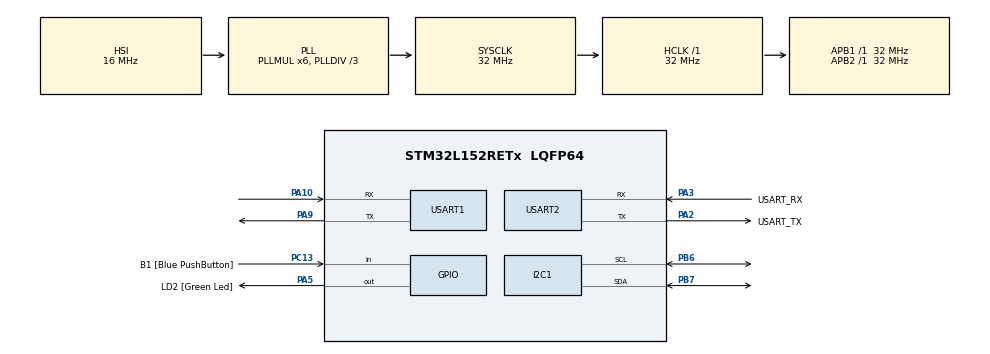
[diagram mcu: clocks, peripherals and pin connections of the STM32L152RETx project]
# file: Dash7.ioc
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Mcu.Family=STM32L1
Mcu.Name=STM32L152RETx
Mcu.Package=LQFP64
NVIC.PriorityGroup=NVIC_PRIORITYGROUP_0
PA10.Mode=Asynchronous
PA10.Signal=USART1_RX
PA13.GPIO_Label=TMS
PA13.Signal=SYS_JTMS-SWDIO
PA14.GPIO_Label=TCK
PA14.Signal=SYS_JTCK-SWCLK
PA2.GPIO_Label=USART_TX
PA2.Mode=Asynchronous
PA2.Signal=USART2_TX
PA3.GPIO_Label=USART_RX
PA3.Mode=Asynchronous
PA3.Signal=USART2_RX
PA5.GPIO_Label=LD2 [Green Led]
PA5.Signal=GPIO_Output
PA9.Mode=Asynchronous
PA9.Signal=USART1_TX
PB3.GPIO_Label=SWO
PB3.Signal=SYS_JTDO-TRACESWO
PB6.Mode=I2C
PB6.Signal=I2C1_SCL
PB7.Mode=I2C
PB7.Signal=I2C1_SDA
PC13-WKUP2.GPIO_Label=B1 [Blue PushButton]
PC13-WKUP2.Signal=GPIO_Input
PC14-OSC32_IN.Signal=RCC_OSC32_IN
PC15-OSC32_OUT.Signal=RCC_OSC32_OUT
PH0-OSC_IN.Signal=RCC_OSC_IN
PH1-OSC_OUT.Signal=RCC_OSC_OUT
ProjectManager.HeapSize=0x200
ProjectManager.StackSize=0x400
ProjectManager.TargetToolchain=EWARM
RCC.AHBFreq_Value=32000000
RCC.APB1Freq_Value=32000000
RCC.APB1TimFreq_Value=32000000
RCC.APB2Freq_Value=32000000
RCC.APB2TimFreq_Value=32000000
RCC.HCLKFreq_Value=32000000
RCC.HSE_VALUE=8000000
RCC.HSI_VALUE=16000000
RCC.LSE_VALUE=32768
RCC.MSI_VALUE=2097000
RCC.PLLDIV=RCC_PLL_DIV3
RCC.PLLMUL=RCC_PLL_MUL6
RCC.RTCClockSelectionVirtual=RCC_RTCCLKSOURCE_LSE
RCC.SYSCLKFreq_VALUE=32000000
RCC.SYSCLKSource=RCC_SYSCLKSOURCE_PLLCLK
RCC.USBOutput=48000000
RCC.VCOOutputFreq_Value=96000000
board=NUCLEO-L152RE

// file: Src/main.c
/**
  ******************************************************************************
  * File Name          : main.c
  * Description        : Main program body
  ******************************************************************************
  *
  * COPYRIGHT(c) 2017 STMicroelectronics
  *
  * Redistribution and use in source and binary forms, with or without modification,
  * are permitted provided that the following conditions are met:
  *   1. Redistributions of source code must retain the above copyright notice,
  *      this list of conditions and the following disclaimer.
  *   2. Redistributions in binary form must reproduce the above copyright notice,
  *      this list of conditions and the following disclaimer in the documentation
  *      and/or other materials provided with the distribution.
  *   3. Neither the name of STMicroelectronics nor the names of its contributors
  *      may be used to endorse or promote products derived from this software
  *      without specific prior written permission.
  *
  * THIS SOFTWARE IS PROVIDED BY THE COPYRIGHT HOLDERS AND CONTRIBUTORS "AS IS"
  * AND ANY EXPRESS OR IMPLIED WARRANTIES, INCLUDING, BUT NOT LIMITED TO, THE
  * IMPLIED WARRANTIES OF MERCHANTABILITY AND FITNESS FOR A PARTICULAR PURPOSE ARE
  * DISCLAIMED. IN NO EVENT SHALL THE COPYRIGHT HOLDER OR CONTRIBUTORS BE LIABLE
  * FOR ANY DIRECT, INDIRECT, INCIDENTAL, SPECIAL, EXEMPLARY, OR CONSEQUENTIAL
  * DAMAGES (INCLUDING, BUT NOT LIMITED TO, PROCUREMENT OF SUBSTITUTE GOODS OR
  * SERVICES; LOSS OF USE, DATA, OR PROFITS; OR BUSINESS INTERRUPTION) HOWEVER
  * CAUSED AND ON ANY THEORY OF LIABILITY, WHETHER IN CONTRACT, STRICT LIABILITY,
  * OR TORT (INCLUDING NEGLIGENCE OR OTHERWISE) ARISING IN ANY WAY OUT OF THE USE
  * OF THIS SOFTWARE, EVEN IF ADVISED OF THE POSSIBILITY OF SUCH DAMAGE.
  *
  ******************************************************************************
  */

#include "main.h"
#include "stm32l1xx_hal.h"

/* USER CODE BEGIN Includes */
/* USER CODE BEGIN Includes */
#ifdef __GNUC__
/* With GCC/RAISONANCE, small printf (option LD Linker->Libraries->Small printf
   set to 'Yes') calls __io_putchar() */
#define PUTCHAR_PROTOTYPE int __io_putchar(int ch)
#else
#define PUTCHAR_PROTOTYPE int fputc(int ch, FILE *f)
#endif /* __GNUC__ */
/* USER CODE END Includes */

I2C_HandleTypeDef hi2c1;

UART_HandleTypeDef huart1;
UART_HandleTypeDef huart2;

/* USER CODE BEGIN PV */
/* Private variables ---------------------------------------------------------*/

/* USER CODE END PV */

void SystemClock_Config(void);
void Error_Handler(void);
void Dash7Send(void);
static void MX_GPIO_Init(void);
static void MX_I2C1_Init(void);
static void MX_USART1_UART_Init(void);
static void MX_USART2_UART_Init(void);

/* USER CODE BEGIN PFP */
/* Private function prototypes -----------------------------------------------*/

/* USER CODE END PFP */

int main(void)
{

  /* MCU Configuration----------------------------------------------------------*/

  /* Reset of all peripherals, Initializes the Flash interface and the Systick. */
  HAL_Init();

  /* Configure the system clock */
  SystemClock_Config();

  /* Initialize all configured peripherals */
  MX_GPIO_Init();
  MX_I2C1_Init();
  MX_USART1_UART_Init();
  MX_USART2_UART_Init();

  /* USER CODE BEGIN 2 */
    uint8_t opt = 0;
    char readBuf[1];
  /* USER CODE END 2 */

  /* Infinite loop */
  while (1)
  {

  /* USER CODE BEGIN 3 */
      if(HAL_GPIO_ReadPin(B1_GPIO_Port, B1_Pin) == GPIO_PIN_RESET) {
	          HAL_GPIO_TogglePin(LD2_GPIO_Port, LD2_Pin);
                  Dash7Send();
	          HAL_Delay(500);
      }

  }
  /* USER CODE END 3 */

}

/*
    -----------------------------FULL COMMAND WITH DATA [0,1] -------------------
    41 54 24 44 c0 00 0e b4 af 32 d7 01 00 10 01 20 01 00 02 00 01
    0x41 0x54 0x24 0x44 0xc0 0x00 0x0e 0xb4 0xaf 0x32 0xd7 0x01 0x00 0x10 0x01 0x20 0x01 0x00 0x02 0x00 0x01
    $41 $54 $24 $44 $c0 $00 $0e $b4 $af $32 $d7 $01 $00 $10 $01 $20 $01 $00 $02 $00 $01

            ---------------------SERIALIZE------------------------
    41 54 24 44 c0 00 0e

        STATIC SER       LENGTH
    [41 54 24 44 c0 00]  [0e]

    ++++++++++++++++ LENGTH ++++++++++++++++
    Length of bytes of the ALP COMMAND

    0e --> 14 --> Length

            ---------------------ALP COMMAND----------------------
    34 af 32 d7 01 00 10 01 20 01 00 02 00 01

      TAG         FORWARD         RETURN FILE DATA
    [34 af] [32 d7 01 00 10 01] [20 01 00 02 00 01]

    ++++++++++++++++ TAG ++++++++++++++++

    ALP COMMAND:
    34 af

    34 --> 52   --> Request Tag
    af --> 175  --> Tag Value (random)

    PARSED: Command with tag 175 (executing)

    ++++++++++++++++ FORWARD ++++++++++++++++

    ALP COMMAND:
    32 d7 01 00 10 01

    32 --> 50    --> Forward
    d7 --> 215   --> Interface Name (D7ASP)
    01 --> 01    --> ResponseMode.RESP_MODE_ANY
    00 --> 00    --> mant
    10 --> 16    --> ??
    01 --> 01    --> access_class

    PARSED:
    actions:
	action: Forward: interface-id=InterfaceType.D7ASP, configuration={'addressee': {'nls_method': <NlsMethod.NONE: 0>, 'access_class': 1,
            '__CLASS__': 'Addressee', 'id_type': <IdType.NOID: 1>, 'id': None}, 'qos': {'record': False, 'resp_mod': <ResponseMode.RESP_MODE_ALL: 1>,
            '__CLASS__': 'QoS', 'retry_mod': <RetryMode.RETRY_MODE_NO: 0>, 'stop_on_err': False}, '__CLASS__': 'Configuration', 'dorm_to': {'mant': 0, '__CLASS__': 'CT', 'exp': 0}}

    ++++++++++++++ RETURN FILE DATA ++++++++++++++++

    ALP COMMAND:
    20 01 00 02 00 01

    20 --> 32   --> Return File Data
    01 --> 01   --> File ID
    00 --> 00   --> Offset
    02 --> 02   --> Length data bytes

    <DATA> [0,1] LENGTH:2
    00 --> 00
    00 --> 01

    PARSED:
    actions:
        action: ReturnFileData: file-id=1, size=1, offset=0, length=2, data=[0, 1]
*/
void Dash7Send(void)
{
  uint8_t message[] = {0x41, 0x54, 0x24, 0x44, 0xc0, 0x00, 0x0e, 0xb4, 0xaf, 0x32, 0xd7, 0x01, 0x00, 0x10, 0x01, 0x20, 0x01, 0x00, 0x02, 0x00, 0x01};
  HAL_UART_Transmit(&huart1, (uint8_t*)message, sizeof(message), HAL_MAX_DELAY);
}

/** System Clock Configuration
*/
void SystemClock_Config(void)
{

  RCC_OscInitTypeDef RCC_OscInitStruct;
  RCC_ClkInitTypeDef RCC_ClkInitStruct;

    /**Configure the main internal regulator output voltage
    */
  __HAL_PWR_VOLTAGESCALING_CONFIG(PWR_REGULATOR_VOLTAGE_SCALE1);

    /**Initializes the CPU, AHB and APB busses clocks
    */
  RCC_OscInitStruct.OscillatorType = RCC_OSCILLATORTYPE_HSI;
  RCC_OscInitStruct.HSIState = RCC_HSI_ON;
  RCC_OscInitStruct.HSICalibrationValue = 16;
  RCC_OscInitStruct.PLL.PLLState = RCC_PLL_ON;
  RCC_OscInitStruct.PLL.PLLSource = RCC_PLLSOURCE_HSI;
  RCC_OscInitStruct.PLL.PLLMUL = RCC_PLL_MUL6;
  RCC_OscInitStruct.PLL.PLLDIV = RCC_PLL_DIV3;
  if (HAL_RCC_OscConfig(&RCC_OscInitStruct) != HAL_OK)
  {
    Error_Handler();
  }

    /**Initializes the CPU, AHB and APB busses clocks
    */
  RCC_ClkInitStruct.ClockType = RCC_CLOCKTYPE_HCLK|RCC_CLOCKTYPE_SYSCLK
                              |RCC_CLOCKTYPE_PCLK1|RCC_CLOCKTYPE_PCLK2;
  RCC_ClkInitStruct.SYSCLKSource = RCC_SYSCLKSOURCE_PLLCLK;
  RCC_ClkInitStruct.AHBCLKDivider = RCC_SYSCLK_DIV1;
  RCC_ClkInitStruct.APB1CLKDivider = RCC_HCLK_DIV1;
  RCC_ClkInitStruct.APB2CLKDivider = RCC_HCLK_DIV1;

  if (HAL_RCC_ClockConfig(&RCC_ClkInitStruct, FLASH_LATENCY_1) != HAL_OK)
  {
    Error_Handler();
  }

    /**Configure the Systick interrupt time
    */
  HAL_SYSTICK_Config(HAL_RCC_GetHCLKFreq()/1000);

    /**Configure the Systick
    */
  HAL_SYSTICK_CLKSourceConfig(SYSTICK_CLKSOURCE_HCLK);

  /* SysTick_IRQn interrupt configuration */
  HAL_NVIC_SetPriority(SysTick_IRQn, 0, 0);
}

/* I2C1 init function */
static void MX_I2C1_Init(void)
{

  hi2c1.Instance = I2C1;
  hi2c1.Init.ClockSpeed = 100000;
  hi2c1.Init.DutyCycle = I2C_DUTYCYCLE_2;
  hi2c1.Init.OwnAddress1 = 0;
  hi2c1.Init.AddressingMode = I2C_ADDRESSINGMODE_7BIT;
  hi2c1.Init.DualAddressMode = I2C_DUALADDRESS_DISABLE;
  hi2c1.Init.OwnAddress2 = 0;
  hi2c1.Init.GeneralCallMode = I2C_GENERALCALL_DISABLE;
  hi2c1.Init.NoStretchMode = I2C_NOSTRETCH_DISABLE;
  if (HAL_I2C_Init(&hi2c1) != HAL_OK)
  {
    Error_Handler();
  }

}

/* USART1 init function */
static void MX_USART1_UART_Init(void)
{

  huart1.Instance = USART1;
  huart1.Init.BaudRate = 115200;
  huart1.Init.WordLength = UART_WORDLENGTH_8B;
  huart1.Init.StopBits = UART_STOPBITS_1;
  huart1.Init.Parity = UART_PARITY_NONE;
  huart1.Init.Mode = UART_MODE_TX_RX;
  huart1.Init.HwFlowCtl = UART_HWCONTROL_NONE;
  huart1.Init.OverSampling = UART_OVERSAMPLING_16;
  if (HAL_UART_Init(&huart1) != HAL_OK)
  {
    Error_Handler();
  }

}

/* USART2 init function */
static void MX_USART2_UART_Init(void)
{

  huart2.Instance = USART2;
  huart2.Init.BaudRate = 115200;
  huart2.Init.WordLength = UART_WORDLENGTH_8B;
  huart2.Init.StopBits = UART_STOPBITS_1;
  huart2.Init.Parity = UART_PARITY_NONE;
  huart2.Init.Mode = UART_MODE_TX_RX;
  huart2.Init.HwFlowCtl = UART_HWCONTROL_NONE;
  huart2.Init.OverSampling = UART_OVERSAMPLING_16;
  if (HAL_UART_Init(&huart2) != HAL_OK)
  {
    Error_Handler();
  }

}

/** Configure pins as
        * Analog
        * Input
        * Output
        * EVENT_OUT
        * EXTI
*/
static void MX_GPIO_Init(void)
{

  GPIO_InitTypeDef GPIO_InitStruct;

  /* GPIO Ports Clock Enable */
  __HAL_RCC_GPIOC_CLK_ENABLE();
  __HAL_RCC_GPIOH_CLK_ENABLE();
  __HAL_RCC_GPIOA_CLK_ENABLE();
  __HAL_RCC_GPIOB_CLK_ENABLE();

  /*Configure GPIO pin : B1_Pin */
  GPIO_InitStruct.Pin = B1_Pin;
  GPIO_InitStruct.Mode = GPIO_MODE_INPUT;
  GPIO_InitStruct.Pull = GPIO_NOPULL;
  HAL_GPIO_Init(B1_GPIO_Port, &GPIO_InitStruct);

  /*Configure GPIO pin : LD2_Pin */
  GPIO_InitStruct.Pin = LD2_Pin;
  GPIO_InitStruct.Mode = GPIO_MODE_OUTPUT_PP;
  GPIO_InitStruct.Pull = GPIO_NOPULL;
  GPIO_InitStruct.Speed = GPIO_SPEED_FREQ_LOW;
  HAL_GPIO_Init(LD2_GPIO_Port, &GPIO_InitStruct);

  /*Configure GPIO pin Output Level */
  HAL_GPIO_WritePin(LD2_GPIO_Port, LD2_Pin, GPIO_PIN_RESET);

}

void Error_Handler(void)
{
  while(1)
  {
  }
}

PUTCHAR_PROTOTYPE
{
  /* Place your implementation of fputc here */
  /* e.g. write a character to the USART3 and Loop until the end of transmission */
  HAL_UART_Transmit(&huart2, (uint8_t *)&ch, 1, 0xFFFF);

  return ch;
}

/************************ (C) COPYRIGHT STMicroelectronics *****END OF FILE****/
